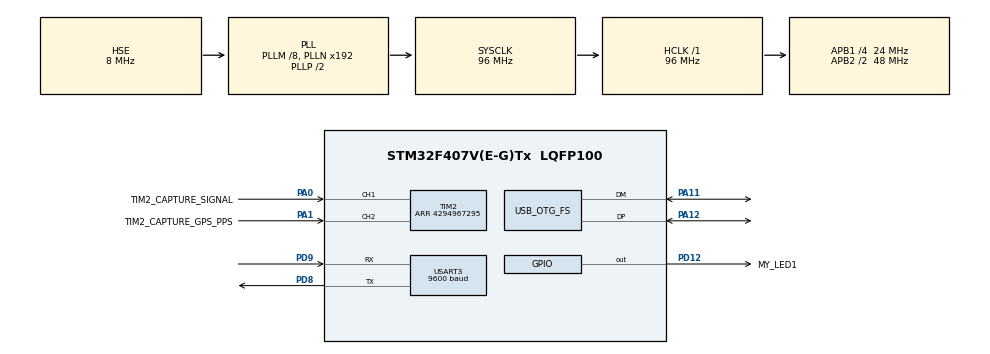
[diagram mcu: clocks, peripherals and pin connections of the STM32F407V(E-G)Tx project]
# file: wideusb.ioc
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FREERTOS.HEAP_NUMBER=3
FREERTOS.Tasks01=defaultTask,0,1024,StartDefaultTask,Default,NULL,Dynamic,NULL,NULL
Mcu.Family=STM32F4
Mcu.Name=STM32F407V(E-G)Tx
Mcu.Package=LQFP100
NVIC.OTG_FS_IRQn=true\:5\:0\:false\:false\:true\:true\:false
NVIC.PriorityGroup=NVIC_PRIORITYGROUP_4
NVIC.TIM2_IRQn=true\:5\:0\:false\:false\:true\:true\:true
NVIC.TIM6_DAC_IRQn=true\:0\:0\:false\:false\:true\:false\:false
NVIC.TimeBase=TIM6_DAC_IRQn
NVIC.TimeBaseIP=TIM6
NVIC.USART3_IRQn=true\:5\:0\:false\:false\:true\:true\:true
PA0-WKUP.GPIO_Label=TIM2_CAPTURE_SIGNAL
PA0-WKUP.Signal=S_TIM2_CH1_ETR
PA1.GPIO_Label=TIM2_CAPTURE_GPS_PPS
PA1.Signal=S_TIM2_CH2
PA11.Mode=Device_Only
PA11.Signal=USB_OTG_FS_DM
PA12.Mode=Device_Only
PA12.Signal=USB_OTG_FS_DP
PD12.GPIO_Label=MY_LED1
PD12.PinState=GPIO_PIN_RESET
PD12.Signal=GPIO_Output
PD8.Mode=Asynchronous
PD8.Signal=USART3_TX
PD9.Mode=Asynchronous
PD9.Signal=USART3_RX
PH0-OSC_IN.Mode=HSE-External-Oscillator
PH0-OSC_IN.Signal=RCC_OSC_IN
PH1-OSC_OUT.Mode=HSE-External-Oscillator
PH1-OSC_OUT.Signal=RCC_OSC_OUT
ProjectManager.HeapSize=0x200
ProjectManager.StackSize=0x400
ProjectManager.TargetToolchain=Makefile
RCC.48MHZClocksFreq_Value=48000000
RCC.AHBFreq_Value=96000000
RCC.APB1CLKDivider=RCC_HCLK_DIV4
RCC.APB1Freq_Value=24000000
RCC.APB1TimFreq_Value=48000000
RCC.APB2CLKDivider=RCC_HCLK_DIV2
RCC.APB2Freq_Value=48000000
RCC.APB2TimFreq_Value=96000000
RCC.CortexFreq_Value=96000000
RCC.HCLKFreq_Value=96000000
RCC.HSE_VALUE=8000000
RCC.HSI_VALUE=16000000
RCC.LSE_VALUE=32768
RCC.PLLM=8
RCC.SYSCLKFreq_VALUE=96000000
RCC.SYSCLKSource=RCC_SYSCLKSOURCE_PLLCLK
RCC.VCOOutputFreq_Value=192000000
SH.S_TIM2_CH1_ETR.0=TIM2_CH1,Input_Capture1_from_TI1
SH.S_TIM2_CH2.0=TIM2_CH2,Input_Capture2_from_TI2
TIM2.Channel-Input_Capture1_from_TI1=TIM_CHANNEL_1
TIM2.Channel-Input_Capture2_from_TI2=TIM_CHANNEL_2
TIM2.Period=4294967295
USART3.BaudRate=9600
USART3.Mode=MODE_TX_RX
USART3.OverSampling=UART_OVERSAMPLING_16
USART3.StopBits=STOPBITS_1
USART3.VirtualMode=VM_ASYNC
USB_DEVICE.APP_RX_DATA_SIZE-CDC_FS=1024
USB_DEVICE.CLASS_NAME_FS=CDC
USB_DEVICE.MANUFACTURER_STRING-CDC_FS=WideUSB Project
USB_DEVICE.PRODUCT_STRING_CDC_FS=WideUSB Virtual ComPort
USB_DEVICE.VirtualMode-CDC_FS=Cdc
USB_DEVICE.VirtualModeFS=Cdc_FS
USB_OTG_FS.VirtualMode=Device_Only
VP_FREERTOS_VS_ENABLE.Mode=Enabled
VP_SYS_VS_tim6.Mode=TIM6
VP_TIM2_VS_ClockSourceINT.Mode=Internal
VP_USB_DEVICE_VS_USB_DEVICE_CDC_FS.Mode=CDC_FS
board=custom

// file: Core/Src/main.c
/* USER CODE BEGIN Header */
/**
  ******************************************************************************
  * @file           : main.c
  * @brief          : Main program body
  ******************************************************************************
  ** This notice applies to any and all portions of this file
  * that are not between comment pairs USER CODE BEGIN and
  * USER CODE END. Other portions of this file, whether
  * inserted by the user or by software development tools
  * are owned by their respective copyright owners.
  *
  * COPYRIGHT(c) 2020 STMicroelectronics
  *
  * Redistribution and use in source and binary forms, with or without modification,
  * are permitted provided that the following conditions are met:
  *   1. Redistributions of source code must retain the above copyright notice,
  *      this list of conditions and the following disclaimer.
  *   2. Redistributions in binary form must reproduce the above copyright notice,
  *      this list of conditions and the following disclaimer in the documentation
  *      and/or other materials provided with the distribution.
  *   3. Neither the name of STMicroelectronics nor the names of its contributors
  *      may be used to endorse or promote products derived from this software
  *      without specific prior written permission.
  *
  * THIS SOFTWARE IS PROVIDED BY THE COPYRIGHT HOLDERS AND CONTRIBUTORS "AS IS"
  * AND ANY EXPRESS OR IMPLIED WARRANTIES, INCLUDING, BUT NOT LIMITED TO, THE
  * IMPLIED WARRANTIES OF MERCHANTABILITY AND FITNESS FOR A PARTICULAR PURPOSE ARE
  * DISCLAIMED. IN NO EVENT SHALL THE COPYRIGHT HOLDER OR CONTRIBUTORS BE LIABLE
  * FOR ANY DIRECT, INDIRECT, INCIDENTAL, SPECIAL, EXEMPLARY, OR CONSEQUENTIAL
  * DAMAGES (INCLUDING, BUT NOT LIMITED TO, PROCUREMENT OF SUBSTITUTE GOODS OR
  * SERVICES; LOSS OF USE, DATA, OR PROFITS; OR BUSINESS INTERRUPTION) HOWEVER
  * CAUSED AND ON ANY THEORY OF LIABILITY, WHETHER IN CONTRACT, STRICT LIABILITY,
  * OR TORT (INCLUDING NEGLIGENCE OR OTHERWISE) ARISING IN ANY WAY OUT OF THE USE
  * OF THIS SOFTWARE, EVEN IF ADVISED OF THE POSSIBILITY OF SUCH DAMAGE.
  *
  ******************************************************************************
  */
/* USER CODE END Header */

#include "main.h"
#include "cmsis_os.h"
#include "tim.h"
#include "usart.h"
#include "usb_device.h"
#include "gpio.h"

void SystemClock_Config(void);
void MX_FREERTOS_Init(void);

int main(void)
{

  /* MCU Configuration--------------------------------------------------------*/

  /* Reset of all peripherals, Initializes the Flash interface and the Systick. */
  HAL_Init();

  /* Configure the system clock */
  SystemClock_Config();

  /* Initialize all configured peripherals */
  MX_GPIO_Init();
  MX_USART3_UART_Init();
  MX_TIM2_Init();

  /* Call init function for freertos objects (in freertos.c) */
  MX_FREERTOS_Init();

  /* Start scheduler */
  osKernelStart();

  /* We should never get here as control is now taken by the scheduler */

  /* Infinite loop */
  while (1)
  {

  }
}

void SystemClock_Config(void)
{
  RCC_OscInitTypeDef RCC_OscInitStruct = {0};
  RCC_ClkInitTypeDef RCC_ClkInitStruct = {0};

  /**Configure the main internal regulator output voltage
  */
  __HAL_RCC_PWR_CLK_ENABLE();
  __HAL_PWR_VOLTAGESCALING_CONFIG(PWR_REGULATOR_VOLTAGE_SCALE1);
  /**Initializes the CPU, AHB and APB busses clocks
  */
  RCC_OscInitStruct.OscillatorType = RCC_OSCILLATORTYPE_HSE;
  RCC_OscInitStruct.HSEState = RCC_HSE_ON;
  RCC_OscInitStruct.PLL.PLLState = RCC_PLL_ON;
  RCC_OscInitStruct.PLL.PLLSource = RCC_PLLSOURCE_HSE;
  RCC_OscInitStruct.PLL.PLLM = 8;
  RCC_OscInitStruct.PLL.PLLN = 192;
  RCC_OscInitStruct.PLL.PLLP = RCC_PLLP_DIV2;
  RCC_OscInitStruct.PLL.PLLQ = 4;
  if (HAL_RCC_OscConfig(&RCC_OscInitStruct) != HAL_OK)
  {
    Error_Handler();
  }
  /**Initializes the CPU, AHB and APB busses clocks
  */
  RCC_ClkInitStruct.ClockType = RCC_CLOCKTYPE_HCLK|RCC_CLOCKTYPE_SYSCLK
                              |RCC_CLOCKTYPE_PCLK1|RCC_CLOCKTYPE_PCLK2;
  RCC_ClkInitStruct.SYSCLKSource = RCC_SYSCLKSOURCE_PLLCLK;
  RCC_ClkInitStruct.AHBCLKDivider = RCC_SYSCLK_DIV1;
  RCC_ClkInitStruct.APB1CLKDivider = RCC_HCLK_DIV4;
  RCC_ClkInitStruct.APB2CLKDivider = RCC_HCLK_DIV2;

  if (HAL_RCC_ClockConfig(&RCC_ClkInitStruct, FLASH_LATENCY_3) != HAL_OK)
  {
    Error_Handler();
  }
}

void HAL_TIM_PeriodElapsedCallback(TIM_HandleTypeDef *htim)
{
  if (htim->Instance == TIM6) {
    HAL_IncTick();
  }
}

void Error_Handler(void)
{
  /* USER CODE BEGIN Error_Handler_Debug */
  /* User can add his own implementation to report the HAL error return state */
    printf("Error_Handler(void) called\r\n");
  /* USER CODE END Error_Handler_Debug */
}

#ifdef  USE_FULL_ASSERT
/**
  * @brief  Reports the name of the source file and the source line number
  *         where the assert_param error has occurred.
  * @param  file: pointer to the source file name
  * @param  line: assert_param error line source number
  * @retval None
  */
void assert_failed(uint8_t *file, uint32_t line)
{
  /* USER CODE BEGIN 6 */
  /* User can add his own implementation to report the file name and line number,
     tex: printf("Wrong parameters value: file %s on line %d\r\n", file, line) */

    // Ok, good enough
    printf("Wrong parameters value: file %s on line %ld\r\n", file, line);
  /* USER CODE END 6 */
}
#endif /* USE_FULL_ASSERT */

/************************ (C) COPYRIGHT STMicroelectronics *****END OF FILE****/

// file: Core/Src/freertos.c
/* USER CODE BEGIN Header */
/**
  ******************************************************************************
  * File Name          : freertos.c
  * Description        : Code for freertos applications
  ******************************************************************************
  * This notice applies to any and all portions of this file
  * that are not between comment pairs USER CODE BEGIN and
  * USER CODE END. Other portions of this file, whether
  * inserted by the user or by software development tools
  * are owned by their respective copyright owners.
  *
  * Copyright (c) 2020 STMicroelectronics International N.V.
  * All rights reserved.
  *
  * Redistribution and use in source and binary forms, with or without
  * modification, are permitted, provided that the following conditions are met:
  *
  * 1. Redistribution of source code must retain the above copyright notice,
  *    this list of conditions and the following disclaimer.
  * 2. Redistributions in binary form must reproduce the above copyright notice,
  *    this list of conditions and the following disclaimer in the documentation
  *    and/or other materials provided with the distribution.
  * 3. Neither the name of STMicroelectronics nor the names of other
  *    contributors to this software may be used to endorse or promote products
  *    derived from this software without specific written permission.
  * 4. This software, including modifications and/or derivative works of this
  *    software, must execute solely and exclusively on microcontroller or
  *    microprocessor devices manufactured by or for STMicroelectronics.
  * 5. Redistribution and use of this software other than as permitted under
  *    this license is void and will automatically terminate your rights under
  *    this license.
  *
  * THIS SOFTWARE IS PROVIDED BY STMICROELECTRONICS AND CONTRIBUTORS "AS IS"
  * AND ANY EXPRESS, IMPLIED OR STATUTORY WARRANTIES, INCLUDING, BUT NOT
  * LIMITED TO, THE IMPLIED WARRANTIES OF MERCHANTABILITY, FITNESS FOR A
  * PARTICULAR PURPOSE AND NON-INFRINGEMENT OF THIRD PARTY INTELLECTUAL PROPERTY
  * RIGHTS ARE DISCLAIMED TO THE FULLEST EXTENT PERMITTED BY LAW. IN NO EVENT
  * SHALL STMICROELECTRONICS OR CONTRIBUTORS BE LIABLE FOR ANY DIRECT, INDIRECT,
  * INCIDENTAL, SPECIAL, EXEMPLARY, OR CONSEQUENTIAL DAMAGES (INCLUDING, BUT NOT
  * LIMITED TO, PROCUREMENT OF SUBSTITUTE GOODS OR SERVICES; LOSS OF USE, DATA,
  * OR PROFITS; OR BUSINESS INTERRUPTION) HOWEVER CAUSED AND ON ANY THEORY OF
  * LIABILITY, WHETHER IN CONTRACT, STRICT LIABILITY, OR TORT (INCLUDING
  * NEGLIGENCE OR OTHERWISE) ARISING IN ANY WAY OUT OF THE USE OF THIS SOFTWARE,
  * EVEN IF ADVISED OF THE POSSIBILITY OF SUCH DAMAGE.
  *
  ******************************************************************************
  */
/* USER CODE END Header */

#include "FreeRTOS.h"
#include "task.h"
#include "main.h"
#include "cmsis_os.h"

/* USER CODE BEGIN Includes */
#include "cpp-bootstrap.h"
/* USER CODE END Includes */

osThreadId defaultTaskHandle;

void StartDefaultTask(void const * argument);

extern void MX_USB_DEVICE_Init(void);
void MX_FREERTOS_Init(void); /* (MISRA C 2004 rule 8.1) */

void MX_FREERTOS_Init(void) {

  /* Create the thread(s) */
  /* definition and creation of defaultTask */
  osThreadDef(defaultTask, StartDefaultTask, osPriorityNormal, 0, 1024);
  defaultTaskHandle = osThreadCreate(osThread(defaultTask), NULL);

}

void StartDefaultTask(void const * argument)
{
  /* init code for USB_DEVICE */
  MX_USB_DEVICE_Init();

  /* USER CODE BEGIN StartDefaultTask */
  /* Infinite loop */
  (void) argument;
  cpp_bootstrap();

  for(;;)
  {
    osDelay(1);
  }
  /* USER CODE END StartDefaultTask */
}

/************************ (C) COPYRIGHT STMicroelectronics *****END OF FILE****/
